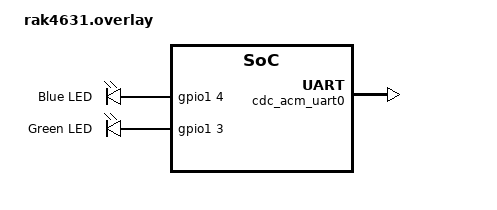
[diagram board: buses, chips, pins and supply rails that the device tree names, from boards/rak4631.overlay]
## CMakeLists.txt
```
# SPDX-License-Identifier: Apache-2.0

cmake_minimum_required(VERSION 3.20.0)

find_package(Zephyr REQUIRED HINTS $ENV{ZEPHYR_BASE})
project(shell)

target_sources(app PRIVATE src/main.c)
target_sources(app PRIVATE src/cli.c)
if(CONFIG_USE_SEGGER_RTT AND CONFIG_BOARD_RAK11720)
  target_sources(app PRIVATE src/rtt.c)
endif()
```

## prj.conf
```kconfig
CONFIG_GPIO=y
CONFIG_SPI=y

CONFIG_MAIN_STACK_SIZE=2048
CONFIG_SYSTEM_WORKQUEUE_STACK_SIZE=2048
CONFIG_BOOT_BANNER=n

# Serial
CONFIG_SERIAL=y
CONFIG_CONSOLE=y

# Lora
CONFIG_LORA=y
CONFIG_LORA_SHELL=y

# Shell settings
CONFIG_SHELL=y
CONFIG_SHELL_BACKEND_SERIAL=y
CONFIG_SHELL_LOG_BACKEND=n

# Logging
CONFIG_LOG=y
CONFIG_LOG_PRINTK=n
CONFIG_USE_SEGGER_RTT=y
CONFIG_LOG_BACKEND_RTT=y
CONFIG_LOG_BACKEND_UART=n
```

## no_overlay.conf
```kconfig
#The aim of this file is to use VS Code inputs.
```

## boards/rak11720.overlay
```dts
/ {
	chosen {
		zephyr,console = &uart0;
		zephyr,shell-uart = &uart0;
	};

	aliases {
		blue-led = &blue_led;
		green-led = &green_led;
	};
};
```

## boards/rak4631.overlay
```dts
/ {
	chosen {
		zephyr,console = &cdc_acm_uart0;
	};

	aliases {
		blue-led = &blue_led;
		green-led = &green_led;
	};

	leds {
		compatible = "gpio-leds";
		blue_led: led_2 {
			gpios = <&gpio1 4 GPIO_ACTIVE_HIGH>;
			label = "Blue LED";
		};
		green_led: led_1 {
			gpios = <&gpio1 3 GPIO_ACTIVE_HIGH>;
			label = "Green LED";
		};
	};
};

&reg1 {
	regulator-initial-mode = <NRF5X_REG_MODE_DCDC>;
};

&zephyr_udc0 {
	cdc_acm_uart0: cdc_acm_uart0 {
		compatible = "zephyr,cdc-acm-uart";
	};
};
```

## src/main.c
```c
#include <zephyr/kernel.h>
#include <zephyr/drivers/gpio.h>

#include <zephyr/logging/log.h>
LOG_MODULE_REGISTER(main, LOG_LEVEL_DBG);

/* 1000 msec = 1 sec */
#define SLEEP_TIME_MS 1000

/*
 * A build error on this line means your board is unsupported.
 * See the sample documentation for information on how to fix this.
 */
static const struct gpio_dt_spec led = GPIO_DT_SPEC_GET(DT_ALIAS(green_led), gpios);

#if defined(CONFIG_BOARD_RAK4631)
static void configure_uicr(void) {
	if ((NRF_UICR->REGOUT0 & UICR_REGOUT0_VOUT_Msk) !=
		(UICR_REGOUT0_VOUT_3V3 << UICR_REGOUT0_VOUT_Pos)) {
		NRF_NVMC->CONFIG = NVMC_CONFIG_WEN_Wen;
		while (NRF_NVMC->READY == NVMC_READY_READY_Busy){}

		NRF_UICR->REGOUT0 = (NRF_UICR->REGOUT0 & ~((uint32_t)UICR_REGOUT0_VOUT_Msk)) |
							(UICR_REGOUT0_VOUT_3V3 << UICR_REGOUT0_VOUT_Pos);

		NRF_NVMC->CONFIG = NVMC_CONFIG_WEN_Ren;
		while (NRF_NVMC->READY == NVMC_READY_READY_Busy){}

		LOG_INF("REGOUT0 is updated!");

		// System reset is needed to update UICR registers.
		NVIC_SystemReset();
	}
}
#endif

int main(void)
{
	int ret = -1;

#if defined(CONFIG_BOARD_RAK4631)
	configure_uicr();
#endif

	if (!gpio_is_ready_dt(&led)) {
		LOG_ERR("LED is not ready!");
	}

	ret = gpio_pin_configure_dt(&led, GPIO_OUTPUT_ACTIVE);
	if (ret) {
		LOG_ERR("Failed to configure LED!");
	}

	ret = gpio_pin_set_dt(&led, 1); // ON
	if (ret) {
		LOG_ERR("Failed to control LED!");
	}
	k_msleep(1000);
	ret = gpio_pin_set_dt(&led, 0); // OFF
	if (ret) {
		LOG_ERR("Failed to control LED!");
	}

	LOG_INF("Shell! %s", CONFIG_BOARD);

	return 0;
}
```

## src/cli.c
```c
#include <zephyr/kernel.h>
#include <zephyr/device.h>
#include <zephyr/shell/shell.h>
#include <zephyr/sys/printk.h>

static int cmd_test_example(const struct shell *shell, size_t argc, char *argv[])
{    
    shell_print(shell, "Testing cmd!!!");
    return 0;
}

SHELL_STATIC_SUBCMD_SET_CREATE(
    test_cli_cmds,

    SHELL_CMD_ARG(test, NULL,
        "trigger a test command",
        cmd_test_example, 0 /* mandatory param */, 0 /* optional param */),

    SHELL_SUBCMD_SET_END
);
 
SHELL_CMD_REGISTER(test_cli, &test_cli_cmds, "TEST CLI", NULL);
```
